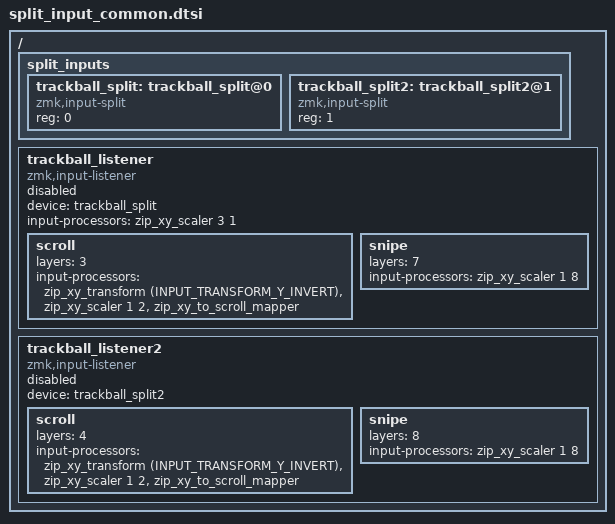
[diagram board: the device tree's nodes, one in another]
#include <dt-bindings/zmk/keys.h>
#include <dt-bindings/zmk/input_transform.h>
#include <input/processors.dtsi>

/ {
  split_inputs {
    #address-cells = <1>;
    #size-cells = <0>;

    trackball_split: trackball_split@0 {
      compatible = "zmk,input-split";
      reg = <0>;
    };
    trackball_split2: trackball_split2@1 {
      compatible = "zmk,input-split";
      reg = <1>;
    };
  };

  trackball_listener: trackball_listener {
    compatible = "zmk,input-listener";
    status = "disabled";
    device = <&trackball_split>;

    input-processors = <&zip_xy_scaler 3 1>;
    scroll {
      layers = <3>;
      input-processors = <&zip_xy_transform (INPUT_TRANSFORM_Y_INVERT)>, <&zip_xy_scaler 1 2>, <&zip_xy_to_scroll_mapper>;
    };
    snipe {
      layers = <7>;
      input-processors = <&zip_xy_scaler 1 8>;
    };
  };

  trackball_listener2: trackball_listener2 {
    compatible = "zmk,input-listener";
    status = "disabled";
    device = <&trackball_split2>;

    scroll {
      layers = <4>;
      input-processors = <&zip_xy_transform (INPUT_TRANSFORM_Y_INVERT)>, <&zip_xy_scaler 1 2>, <&zip_xy_to_scroll_mapper>;
    };
    snipe {
      layers = <8>;
      input-processors = <&zip_xy_scaler 1 8>;
    };
  };
};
